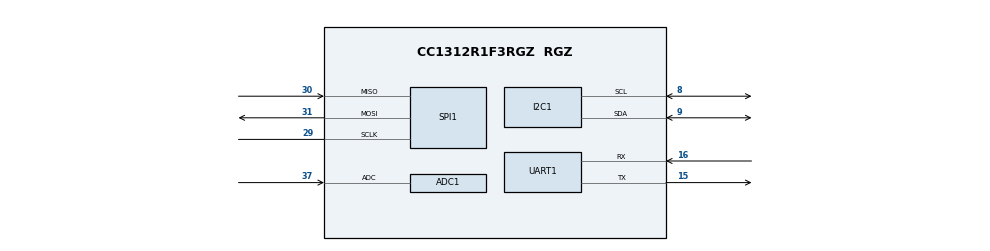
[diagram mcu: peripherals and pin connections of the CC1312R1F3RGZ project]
/**
 * @cliArgs --device "CC1312R1F3RGZ" --package "RGZ" --part "Default" --product "simplelink_cc13x2_26x2_sdk@5.20.00.52"
 * @versions {"data":"2021060817","timestamp":"2021060817","tool":"1.8.2+1992","templates":null}
 */

/**
 * Import the modules used in this configuration.
 */
const CCFG      = scripting.addModule("/ti/devices/CCFG");
const rfdesign  = scripting.addModule("/ti/devices/radioconfig/rfdesign");
const ADC       = scripting.addModule("/ti/drivers/ADC", {}, false);
const ADC1      = ADC.addInstance();
const Board     = scripting.addModule("/ti/drivers/Board");
const I2C       = scripting.addModule("/ti/drivers/I2C", {}, false);
const I2C1      = I2C.addInstance();
const NVS       = scripting.addModule("/ti/drivers/NVS", {}, false);
const NVS1      = NVS.addInstance();
const RF        = scripting.addModule("/ti/drivers/RF");
const RTOS      = scripting.addModule("/ti/drivers/RTOS");
const SPI       = scripting.addModule("/ti/drivers/SPI", {}, false);
const SPI1      = SPI.addInstance();
const TRNG      = scripting.addModule("/ti/drivers/TRNG", {}, false);
const TRNG1     = TRNG.addInstance();
const UART      = scripting.addModule("/ti/drivers/UART", {}, false);
const UART1     = UART.addInstance();
const Watchdog  = scripting.addModule("/ti/drivers/Watchdog", {}, false);
const Watchdog1 = Watchdog.addInstance();
const easylink  = scripting.addModule("/ti/easylink/easylink");

/**
 * Write custom configuration values to the imported modules.
 */
CCFG.enableBootloader         = true;
CCFG.enableBootloaderBackdoor = true;
CCFG.dioBootloaderBackdoor    = 13;
CCFG.levelBootloaderBackdoor  = "Active low";
CCFG.ccfgTemplate.$name       = "ti_devices_CCFGTemplate0";

ADC1.$name                = "CONFIG_ADC_0";
ADC1.adc.adcPin.$assign   = "37";
ADC1.adcPinInstance.$name = "CONFIG_PIN_0";

Board.generateInitializationFunctions = false;

I2C1.$name                = "CONFIG_I2C_0";
I2C1.i2c.sdaPin.$assign   = "9";
I2C1.i2c.sclPin.$assign   = "8";
I2C1.sdaPinInstance.$name = "CONFIG_PIN_1";
I2C1.clkPinInstance.$name = "CONFIG_PIN_2";

NVS1.$name               = "CONFIG_NVS_0";
NVS1.internalFlash.$name = "ti_drivers_nvs_NVSCC26XX0";

SPI1.$name                 = "CONFIG_SPI_0";
SPI1.spi.sclkPin.$assign   = "29";
SPI1.spi.misoPin.$assign   = "30";
SPI1.spi.mosiPin.$assign   = "31";
SPI1.sclkPinInstance.$name = "CONFIG_PIN_5";
SPI1.misoPinInstance.$name = "CONFIG_PIN_6";
SPI1.mosiPinInstance.$name = "CONFIG_PIN_7";

TRNG1.$name = "CONFIG_TRNG_0";

UART1.$name               = "CONFIG_UART_0";
UART1.uart.txPin.$assign  = "15";
UART1.uart.rxPin.$assign  = "16";
UART1.txPinInstance.$name = "CONFIG_PIN_3";
UART1.rxPinInstance.$name = "CONFIG_PIN_4";

Watchdog1.$name = "CONFIG_WATCHDOG_0";

easylink.addrSize                                               = 8;
easylink.EasyLink_Phy_5kbpsSlLr                                 = true;
easylink.EasyLink_Phy_Custom                                    = false;
easylink.radioConfigEasylinkPhy5kbpssllr.codeExportConfig.$name = "ti_devices_radioconfig_code_export_param1";

/**
 * Pinmux solution for unlocked pins/peripherals. This ensures that minor changes to the automatic solver in a future
 * version of the tool will not impact the pinmux you originally saw.  These lines can be completely deleted in order to
 * re-solve from scratch.
 */
ADC1.adc.$suggestSolution              = "ADC0";
I2C1.i2c.$suggestSolution              = "I2C0";
SPI1.spi.$suggestSolution              = "SSI0";
SPI1.spi.dmaRxChannel.$suggestSolution = "DMA_CH3";
SPI1.spi.dmaTxChannel.$suggestSolution = "DMA_CH4";
UART1.uart.$suggestSolution            = "UART0";
Watchdog1.watchdog.$suggestSolution    = "WDT0";
